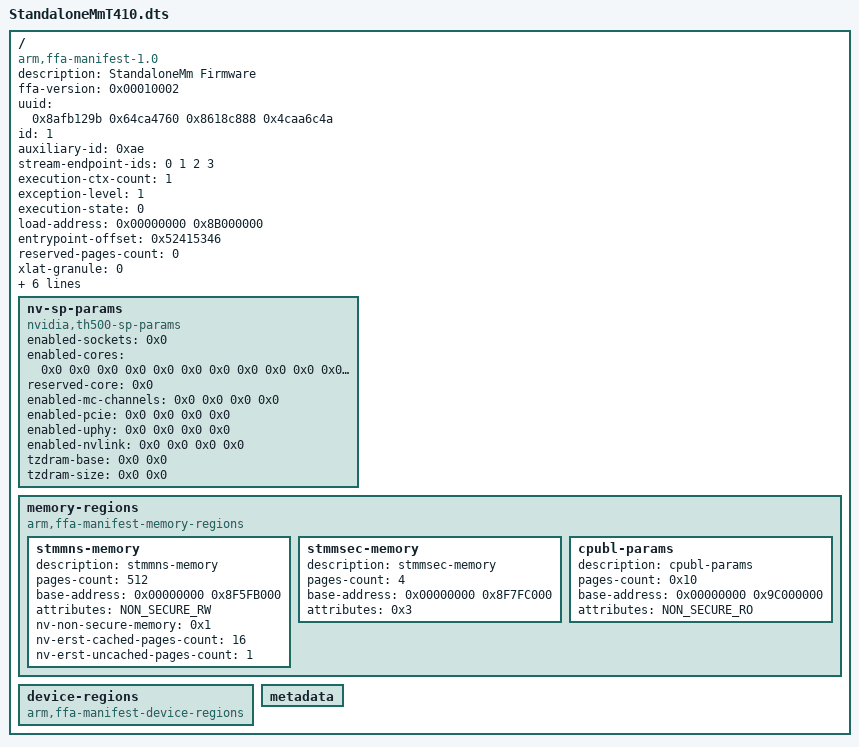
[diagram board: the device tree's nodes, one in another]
/*
 * SPDX-FileCopyrightText: Copyright (c) 2025-2026 NVIDIA CORPORATION & AFFILIATES. All rights reserved.
 *
 * SPDX-License-Identifier: BSD-3-Clause
 *
 * Partition manifest for the StandaloneMmT410 Secure Partition. 
 *
 */

/dts-v1/;

/ {
#define SECURE_RO		0x1
#define SECURE_RW		0x3
#define SECURE_EXECUTE_RO 	0x5
#define SECURE_EXECUTE_RW 	0x7
#define NON_SECURE_RO 		0x9
#define NON_SECURE_RW 		0xB
#define NON_SECURE_EXECUTE_RO 	0xD
#define NON_SECURE_EXECUTE_RW 	0xF

	compatible = "arm,ffa-manifest-1.0";

	/* Properties */
	description = "StandaloneMm Firmware";
	ffa-version = <0x00010002>; /* 31:16 - Major, 15:0 - Minor */
	uuid = <0x8afb129b 0x64ca4760 0x8618c888 0x4caa6c4a>;
	id = <1>;
	auxiliary-id = <0xae>;
	stream-endpoint-ids = <0 1 2 3>;
	execution-ctx-count = <1>;
	exception-level = <1>; /* S-EL0 */
	execution-state = <0>; /* AARCH64 */
	load-address = <0x00000000 0x8B000000>;
	entrypoint-offset = <0x52415346>; /* Magic value to get sptool.py to patch it */
	reserved-pages-count = <0>;
	xlat-granule = <0>; /* 4KiB */
	boot-order = <1>;
	messaging-method = <3>; /* Direct messaging with managed exit */
	run-time-model = <0>; /* Run to completion */
	ns-interrupts-action = <0>; /* Non-secure interrupt is queued */
	other-s-interrupts-action = <0>; /* Other-Secure interrupt is queued */

	/* Boot protocol */
	gp-register-num = <0x0>;

	nv-sp-params {
		compatible = "nvidia,th500-sp-params";
		enabled-sockets = <0x0>;
		enabled-cores = <0x0 0x0 0x0 0x0
				0x0 0x0 0x0 0x0
				0x0 0x0 0x0 0x0
				0x0 0x0 0x0 0x0>;
		reserved-core = <0x0>;
		enabled-mc-channels = <0x0 0x0 0x0 0x0>;
		enabled-pcie = <0x0 0x0 0x0 0x0>;
		enabled-uphy = <0x0 0x0 0x0 0x0>;
		enabled-nvlink = <0x0 0x0 0x0 0x0>;
		tzdram-base = <0x0 0x0>;
		tzdram-size = <0x0 0x0>;
	};

	memory-regions {
		compatible = "arm,ffa-manifest-memory-regions";

		/* Shared memory between StMM and NS world */
		stmmns-memory {
			description = "stmmns-memory";
			pages-count = <512>;
			base-address = <0x00000000 0x8F5FB000>;
			attributes = <NON_SECURE_RW>; /* read-write */
			nv-non-secure-memory = <0x1>;
			nv-erst-cached-pages-count = <16>;
			nv-erst-uncached-pages-count = <1>;
		};

		stmmsec-memory {
			description = "stmmsec-memory";
			pages-count = <4>;
			base-address = <0x00000000 0x8F7FC000>;
			attributes = <0x3>; /* read-write */
		};
		cpubl-params {
			description  = "cpubl-params";
			pages-count  = < 0x10 >;
			base-address = < 0x00000000 0x9C000000 >;
			attributes   = <NON_SECURE_RO>; /* read-only */
		};
	};

	device-regions {
		compatible = "arm,ffa-manifest-device-regions";
		#include "StmmT410DeviceRegions.dtsi"
	};

	metadata {
	};
};
